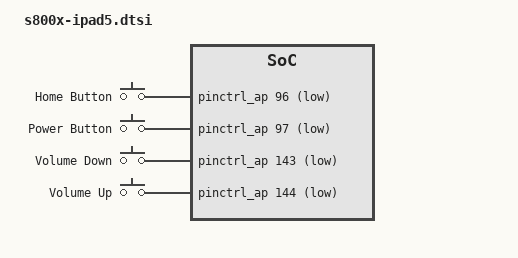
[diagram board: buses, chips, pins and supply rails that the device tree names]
// SPDX-License-Identifier: GPL-2.0+ OR MIT
/*
 * Apple iPad 5 common device tree
 *
 * Copyright (c) 2022, Konrad Dybcio <konradybcio@kernel.org>
 */

#include "s800-0-3-common.dtsi"
#include <dt-bindings/input/input.h>

/ {
	chassis-type = "tablet";

	gpio-keys {
		compatible = "gpio-keys";

		button-home {
			label = "Home Button";
			gpios = <&pinctrl_ap 96 GPIO_ACTIVE_LOW>;
			linux,code = <KEY_HOMEPAGE>;
			wakeup-source;
		};

		button-power {
			label = "Power Button";
			gpios = <&pinctrl_ap 97 GPIO_ACTIVE_LOW>;
			linux,code = <KEY_POWER>;
			wakeup-source;
		};

		button-voldown {
			label = "Volume Down";
			gpios = <&pinctrl_ap 143 GPIO_ACTIVE_LOW>;
			linux,code = <KEY_VOLUMEDOWN>;
		};

		button-volup {
			label = "Volume Up";
			gpios = <&pinctrl_ap 144 GPIO_ACTIVE_LOW>;
			linux,code = <KEY_VOLUMEUP>;
		};
	};
};

&framebuffer0 {
	power-domains = <&ps_disp0 &ps_dp>;
};
